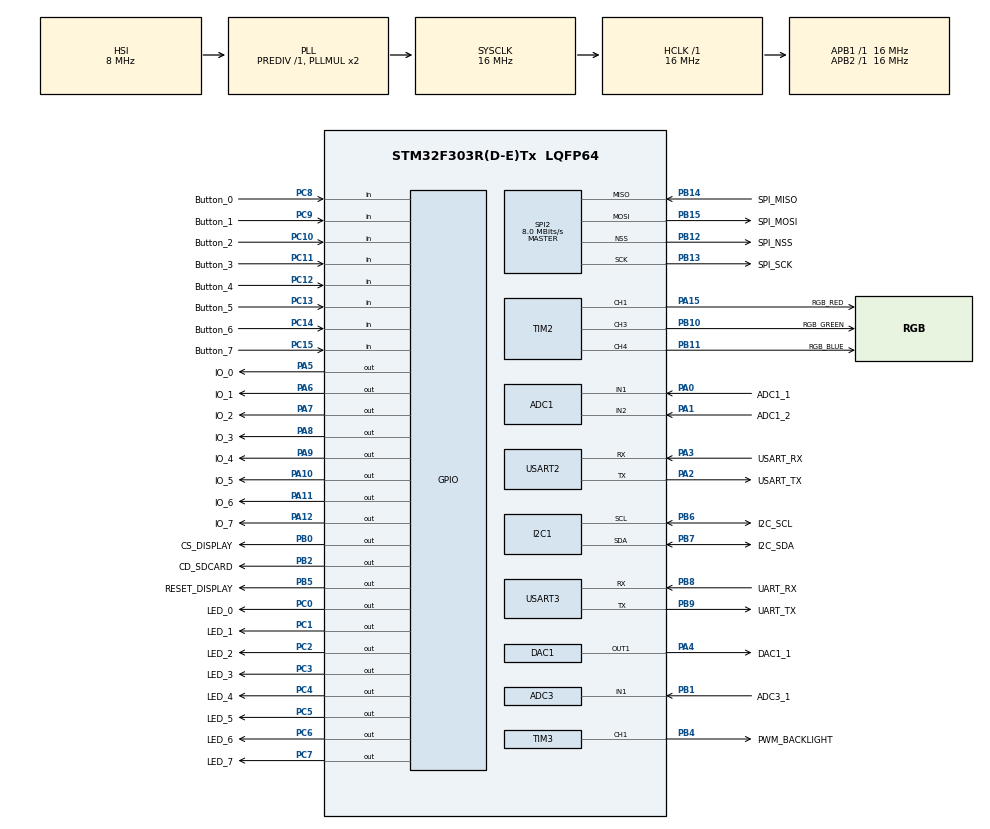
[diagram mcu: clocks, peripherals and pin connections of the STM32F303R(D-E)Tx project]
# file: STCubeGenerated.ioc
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ADC1.Channel-0\#ChannelRegularConversion=ADC_CHANNEL_1
ADC1.NbrOfConversionFlag=1
ADC1.Offset-0\#ChannelRegularConversion=0
ADC1.OffsetNumber-0\#ChannelRegularConversion=ADC_OFFSET_NONE
ADC1.Rank-0\#ChannelRegularConversion=1
ADC1.SamplingTime-0\#ChannelRegularConversion=ADC_SAMPLETIME_1CYCLE_5
ADC1.SingleDiff-0\#ChannelRegularConversion=ADC_DIFFERENTIAL_ENDED
ADC1.master=1
ADC3.Channel-0\#ChannelRegularConversion=ADC_CHANNEL_1
ADC3.NbrOfConversionFlag=1
ADC3.Offset-0\#ChannelRegularConversion=0
ADC3.OffsetNumber-0\#ChannelRegularConversion=ADC_OFFSET_NONE
ADC3.Rank-0\#ChannelRegularConversion=1
ADC3.SamplingTime-0\#ChannelRegularConversion=ADC_SAMPLETIME_1CYCLE_5
ADC3.master=1
Mcu.Family=STM32F3
Mcu.Name=STM32F303R(D-E)Tx
Mcu.Package=LQFP64
NVIC.PriorityGroup=NVIC_PRIORITYGROUP_0
PA0.GPIO_Label=ADC1_1
PA0.Mode=IN1-Differential
PA0.Signal=ADC1_IN1
PA1.GPIO_Label=ADC1_2
PA1.Mode=IN1-Differential
PA1.Signal=ADC1_IN2
PA10.GPIO_Label=IO_5
PA10.Signal=GPIO_Output
PA11.GPIO_Label=IO_6
PA11.Signal=GPIO_Output
PA12.GPIO_Label=IO_7
PA12.Signal=GPIO_Output
PA13.GPIO_Label=TMS
PA13.Mode=Serial_Wire
PA13.Signal=SYS_JTMS-SWDIO
PA14.GPIO_Label=TCK
PA14.Mode=Serial_Wire
PA14.Signal=SYS_JTCK-SWCLK
PA15.GPIO_Label=RGB_RED
PA15.Signal=S_TIM2_CH1_ETR
PA2.GPIO_Label=USART_TX
PA2.GPIO_Mode=GPIO_MODE_AF_PP
PA2.GPIO_PuPd=GPIO_NOPULL
PA2.GPIO_Speed=GPIO_SPEED_FREQ_LOW
PA2.Mode=Asynchronous
PA2.Signal=USART2_TX
PA3.GPIO_Label=USART_RX
PA3.GPIO_Mode=GPIO_MODE_AF_PP
PA3.GPIO_PuPd=GPIO_NOPULL
PA3.GPIO_Speed=GPIO_SPEED_FREQ_LOW
PA3.Mode=Asynchronous
PA3.Signal=USART2_RX
PA4.GPIO_Label=DAC1_1
PA4.Signal=COMP_DAC11_group
PA5.GPIO_Label=IO_0
PA5.Signal=GPIO_Output
PA6.GPIO_Label=IO_1
PA6.Signal=GPIO_Output
PA7.GPIO_Label=IO_2
PA7.Signal=GPIO_Output
PA8.GPIO_Label=IO_3
PA8.Signal=GPIO_Output
PA9.GPIO_Label=IO_4
PA9.Signal=GPIO_Output
PB0.GPIO_Label=CS_DISPLAY
PB0.Signal=GPIO_Output
PB1.GPIO_Label=ADC3_1
PB1.Mode=IN1-Single-Ended
PB1.Signal=ADC3_IN1
PB10.GPIO_Label=RGB_GREEN
PB10.Signal=S_TIM2_CH3
PB11.GPIO_Label=RGB_BLUE
PB11.Signal=S_TIM2_CH4
PB12.GPIO_Label=SPI_NSS
PB12.Mode=NSS_Signal_Hard_Output
PB12.Signal=SPI2_NSS
PB13.GPIO_Label=SPI_SCK
PB13.Mode=Full_Duplex_Master
PB13.Signal=SPI2_SCK
PB14.GPIO_Label=SPI_MISO
PB14.Mode=Full_Duplex_Master
PB14.Signal=SPI2_MISO
PB15.GPIO_Label=SPI_MOSI
PB15.Mode=Full_Duplex_Master
PB15.Signal=SPI2_MOSI
PB2.GPIO_Label=CD_SDCARD
PB2.Signal=GPIO_Output
PB3.GPIO_Label=SWO
PB3.Signal=SYS_JTDO-TRACESWO
PB4.GPIO_Label=PWM_BACKLIGHT
PB4.Signal=S_TIM3_CH1
PB5.GPIO_Label=RESET_DISPLAY
PB5.Signal=GPIO_Output
PB6.GPIO_Label=I2C_SCL
PB6.GPIO_Pu=GPIO_PULLUP
PB6.Mode=I2C
PB6.Signal=I2C1_SCL
PB7.GPIO_Label=I2C_SDA
PB7.GPIO_Pu=GPIO_PULLUP
PB7.Mode=I2C
PB7.Signal=I2C1_SDA
PB8.GPIO_Label=UART_RX
PB8.Mode=Asynchronous
PB8.Signal=USART3_RX
PB9.GPIO_Label=UART_TX
PB9.Mode=Asynchronous
PB9.Signal=USART3_TX
PC0.GPIO_Label=LED_0
PC0.Signal=GPIO_Output
PC1.GPIO_Label=LED_1
PC1.Signal=GPIO_Output
PC10.GPIO_Label=Button_2
PC10.Signal=GPIO_Input
PC11.GPIO_Label=Button_3
PC11.Signal=GPIO_Input
PC12.GPIO_Label=Button_4
PC12.Signal=GPIO_Input
PC13.GPIO_Label=Button_5
PC13.Signal=GPIO_Input
PC14-OSC32_IN.GPIO_Label=Button_6
PC14-OSC32_IN.GPIO_PuPd=GPIO_NOPULL
PC14-OSC32_IN.Signal=GPIO_Input
PC15-OSC32_OUT.GPIO_Label=Button_7
PC15-OSC32_OUT.GPIO_PuPd=GPIO_NOPULL
PC15-OSC32_OUT.Signal=GPIO_Input
PC2.GPIO_Label=LED_2
PC2.Signal=GPIO_Output
PC3.GPIO_Label=LED_3
PC3.Signal=GPIO_Output
PC4.GPIO_Label=LED_4
PC4.Signal=GPIO_Output
PC5.GPIO_Label=LED_5
PC5.Signal=GPIO_Output
PC6.GPIO_Label=LED_6
PC6.Signal=GPIO_Output
PC7.GPIO_Label=LED_7
PC7.Signal=GPIO_Output
PC8.GPIO_Label=Button_0
PC8.Signal=GPIO_Input
PC9.GPIO_Label=Button_1
PC9.Signal=GPIO_Input
PF0-OSC_IN.Signal=RCC_OSC_IN
PF1-OSC_OUT.Signal=RCC_OSC_OUT
ProjectManager.HeapSize=0x200
ProjectManager.StackSize=0x400
ProjectManager.TargetToolchain=MDK-ARM V5.32
RCC.AHBFreq_Value=16000000
RCC.APB1Freq_Value=16000000
RCC.APB1TimFreq_Value=16000000
RCC.APB2Freq_Value=16000000
RCC.APB2TimFreq_Value=16000000
RCC.CortexFreq_Value=16000000
RCC.HCLKFreq_Value=16000000
RCC.HSE_VALUE=8000000
RCC.HSI_VALUE=8000000
RCC.LSE_VALUE=32768
RCC.SYSCLKFreq_VALUE=16000000
RCC.SYSCLKSourceVirtual=RCC_SYSCLKSOURCE_PLLCLK
RCC.USBFreq_Value=16000000
SH.COMP_DAC11_group.0=DAC1_OUT1,DAC_OUT1
SH.S_TIM2_CH1_ETR.0=TIM2_CH1,PWM Generation1 CH1
SH.S_TIM2_CH3.0=TIM2_CH3,PWM Generation3 CH3
SH.S_TIM2_CH4.0=TIM2_CH4,PWM Generation4 CH4
SH.S_TIM3_CH1.0=TIM3_CH1,PWM Generation1 CH1
SPI2.CalculateBaudRate=8.0 MBits/s
SPI2.Direction=SPI_DIRECTION_2LINES
SPI2.Mode=SPI_MODE_MASTER
SPI2.VirtualNSS=VM_NSSHARD
SPI2.VirtualType=VM_MASTER
TIM2.Channel-PWM\ Generation1\ CH1=TIM_CHANNEL_1
TIM2.Channel-PWM\ Generation3\ CH3=TIM_CHANNEL_3
TIM2.Channel-PWM\ Generation4\ CH4=TIM_CHANNEL_4
TIM3.Channel-PWM\ Generation1\ CH1=TIM_CHANNEL_1
USART2.VirtualMode-Asynchronous=VM_ASYNC
USART3.VirtualMode-Asynchronous=VM_ASYNC
board=NUCLEO-F303RE

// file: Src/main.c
/* USER CODE BEGIN Header */
/**
  ******************************************************************************
  * @file           : main.c
  * @brief          : Main program body
  ******************************************************************************
  * @attention
  *
  * Copyright (c) 2022 STMicroelectronics.
  * All rights reserved.
  *
  * This software is licensed under terms that can be found in the LICENSE file
  * in the root directory of this software component.
  * If no LICENSE file comes with this software, it is provided AS-IS.
  *
  ******************************************************************************
  */
/* USER CODE END Header */
#include "main.h"

/* USER CODE BEGIN PD */
#define BUTTONS	(*((volatile uint32_t *) (0x48000800 + 0x10 + 1)))		// BASE Address PORT C + Offset for Input Register + Byte Shift (>> 8, to skip LEDs)
#define LEDS		(*((volatile uint32_t *) (0x48000800 + 0x14)))				// BASE Address PORT C + Offset for Output Register

/* USER CODE END PD */

ADC_HandleTypeDef hadc1;
ADC_HandleTypeDef hadc3;

DAC_HandleTypeDef hdac1;

I2C_HandleTypeDef hi2c1;

SPI_HandleTypeDef hspi2;

TIM_HandleTypeDef htim2;
TIM_HandleTypeDef htim3;

UART_HandleTypeDef huart2;
UART_HandleTypeDef huart3;

void SystemClock_Config(void);
static void MX_GPIO_Init(void);
static void MX_ADC1_Init(void);
static void MX_ADC3_Init(void);
static void MX_DAC1_Init(void);
static void MX_I2C1_Init(void);
static void MX_SPI2_Init(void);
static void MX_TIM2_Init(void);
static void MX_TIM3_Init(void);
static void MX_USART2_UART_Init(void);
static void MX_USART3_UART_Init(void);

int main(void)
{

  /* MCU Configuration--------------------------------------------------------*/

  /* Reset of all peripherals, Initializes the Flash interface and the Systick. */
  HAL_Init();

  /* Configure the system clock */
  SystemClock_Config();

  /* Initialize all configured peripherals */
  MX_GPIO_Init();
  MX_ADC1_Init();
  MX_ADC3_Init();
  MX_DAC1_Init();
  MX_I2C1_Init();
  MX_SPI2_Init();
  MX_TIM2_Init();
  MX_TIM3_Init();
  MX_USART2_UART_Init();
  MX_USART3_UART_Init();

  /* Infinite loop */
  while (1)
  {

    /* USER CODE BEGIN 3 */
		unsigned char buttons = BUTTONS;
		LEDS = buttons;
  }
  /* USER CODE END 3 */
}

void SystemClock_Config(void)
{
  RCC_OscInitTypeDef RCC_OscInitStruct = {0};
  RCC_ClkInitTypeDef RCC_ClkInitStruct = {0};
  RCC_PeriphCLKInitTypeDef PeriphClkInit = {0};

  /** Initializes the RCC Oscillators according to the specified parameters
  * in the RCC_OscInitTypeDef structure.
  */
  RCC_OscInitStruct.OscillatorType = RCC_OSCILLATORTYPE_HSI;
  RCC_OscInitStruct.HSIState = RCC_HSI_ON;
  RCC_OscInitStruct.HSICalibrationValue = RCC_HSICALIBRATION_DEFAULT;
  RCC_OscInitStruct.PLL.PLLState = RCC_PLL_ON;
  RCC_OscInitStruct.PLL.PLLSource = RCC_PLLSOURCE_HSI;
  RCC_OscInitStruct.PLL.PLLMUL = RCC_PLL_MUL2;
  RCC_OscInitStruct.PLL.PREDIV = RCC_PREDIV_DIV1;
  if (HAL_RCC_OscConfig(&RCC_OscInitStruct) != HAL_OK)
  {
    Error_Handler();
  }

  /** Initializes the CPU, AHB and APB buses clocks
  */
  RCC_ClkInitStruct.ClockType = RCC_CLOCKTYPE_HCLK|RCC_CLOCKTYPE_SYSCLK
                              |RCC_CLOCKTYPE_PCLK1|RCC_CLOCKTYPE_PCLK2;
  RCC_ClkInitStruct.SYSCLKSource = RCC_SYSCLKSOURCE_PLLCLK;
  RCC_ClkInitStruct.AHBCLKDivider = RCC_SYSCLK_DIV1;
  RCC_ClkInitStruct.APB1CLKDivider = RCC_HCLK_DIV1;
  RCC_ClkInitStruct.APB2CLKDivider = RCC_HCLK_DIV1;

  if (HAL_RCC_ClockConfig(&RCC_ClkInitStruct, FLASH_LATENCY_0) != HAL_OK)
  {
    Error_Handler();
  }
  PeriphClkInit.PeriphClockSelection = RCC_PERIPHCLK_USART2|RCC_PERIPHCLK_USART3
                              |RCC_PERIPHCLK_I2C1|RCC_PERIPHCLK_ADC12
                              |RCC_PERIPHCLK_ADC34|RCC_PERIPHCLK_TIM2
                              |RCC_PERIPHCLK_TIM34;
  PeriphClkInit.Usart2ClockSelection = RCC_USART2CLKSOURCE_PCLK1;
  PeriphClkInit.Usart3ClockSelection = RCC_USART3CLKSOURCE_PCLK1;
  PeriphClkInit.Adc12ClockSelection = RCC_ADC12PLLCLK_DIV1;
  PeriphClkInit.Adc34ClockSelection = RCC_ADC34PLLCLK_DIV1;
  PeriphClkInit.I2c1ClockSelection = RCC_I2C1CLKSOURCE_HSI;
  PeriphClkInit.Tim2ClockSelection = RCC_TIM2CLK_HCLK;
  PeriphClkInit.Tim34ClockSelection = RCC_TIM34CLK_HCLK;
  if (HAL_RCCEx_PeriphCLKConfig(&PeriphClkInit) != HAL_OK)
  {
    Error_Handler();
  }
}

static void MX_ADC1_Init(void)
{

  ADC_MultiModeTypeDef multimode = {0};
  ADC_ChannelConfTypeDef sConfig = {0};

  /** Common config
  */
  hadc1.Instance = ADC1;
  hadc1.Init.ClockPrescaler = ADC_CLOCK_ASYNC_DIV1;
  hadc1.Init.Resolution = ADC_RESOLUTION_12B;
  hadc1.Init.ScanConvMode = ADC_SCAN_DISABLE;
  hadc1.Init.ContinuousConvMode = DISABLE;
  hadc1.Init.DiscontinuousConvMode = DISABLE;
  hadc1.Init.ExternalTrigConvEdge = ADC_EXTERNALTRIGCONVEDGE_NONE;
  hadc1.Init.ExternalTrigConv = ADC_SOFTWARE_START;
  hadc1.Init.DataAlign = ADC_DATAALIGN_RIGHT;
  hadc1.Init.NbrOfConversion = 1;
  hadc1.Init.DMAContinuousRequests = DISABLE;
  hadc1.Init.EOCSelection = ADC_EOC_SINGLE_CONV;
  hadc1.Init.LowPowerAutoWait = DISABLE;
  hadc1.Init.Overrun = ADC_OVR_DATA_OVERWRITTEN;
  if (HAL_ADC_Init(&hadc1) != HAL_OK)
  {
    Error_Handler();
  }

  /** Configure the ADC multi-mode
  */
  multimode.Mode = ADC_MODE_INDEPENDENT;
  if (HAL_ADCEx_MultiModeConfigChannel(&hadc1, &multimode) != HAL_OK)
  {
    Error_Handler();
  }

  /** Configure Regular Channel
  */
  sConfig.Channel = ADC_CHANNEL_1;
  sConfig.Rank = ADC_REGULAR_RANK_1;
  sConfig.SingleDiff = ADC_DIFFERENTIAL_ENDED;
  sConfig.SamplingTime = ADC_SAMPLETIME_1CYCLE_5;
  sConfig.OffsetNumber = ADC_OFFSET_NONE;
  sConfig.Offset = 0;
  if (HAL_ADC_ConfigChannel(&hadc1, &sConfig) != HAL_OK)
  {
    Error_Handler();
  }

}

static void MX_ADC3_Init(void)
{

  ADC_MultiModeTypeDef multimode = {0};
  ADC_ChannelConfTypeDef sConfig = {0};

  /** Common config
  */
  hadc3.Instance = ADC3;
  hadc3.Init.ClockPrescaler = ADC_CLOCK_ASYNC_DIV1;
  hadc3.Init.Resolution = ADC_RESOLUTION_12B;
  hadc3.Init.ScanConvMode = ADC_SCAN_DISABLE;
  hadc3.Init.ContinuousConvMode = DISABLE;
  hadc3.Init.DiscontinuousConvMode = DISABLE;
  hadc3.Init.ExternalTrigConvEdge = ADC_EXTERNALTRIGCONVEDGE_NONE;
  hadc3.Init.ExternalTrigConv = ADC_SOFTWARE_START;
  hadc3.Init.DataAlign = ADC_DATAALIGN_RIGHT;
  hadc3.Init.NbrOfConversion = 1;
  hadc3.Init.DMAContinuousRequests = DISABLE;
  hadc3.Init.EOCSelection = ADC_EOC_SINGLE_CONV;
  hadc3.Init.LowPowerAutoWait = DISABLE;
  hadc3.Init.Overrun = ADC_OVR_DATA_OVERWRITTEN;
  if (HAL_ADC_Init(&hadc3) != HAL_OK)
  {
    Error_Handler();
  }

  /** Configure the ADC multi-mode
  */
  multimode.Mode = ADC_MODE_INDEPENDENT;
  if (HAL_ADCEx_MultiModeConfigChannel(&hadc3, &multimode) != HAL_OK)
  {
    Error_Handler();
  }

  /** Configure Regular Channel
  */
  sConfig.Channel = ADC_CHANNEL_1;
  sConfig.Rank = ADC_REGULAR_RANK_1;
  sConfig.SingleDiff = ADC_SINGLE_ENDED;
  sConfig.SamplingTime = ADC_SAMPLETIME_1CYCLE_5;
  sConfig.OffsetNumber = ADC_OFFSET_NONE;
  sConfig.Offset = 0;
  if (HAL_ADC_ConfigChannel(&hadc3, &sConfig) != HAL_OK)
  {
    Error_Handler();
  }

}

static void MX_DAC1_Init(void)
{

  DAC_ChannelConfTypeDef sConfig = {0};

  /** DAC Initialization
  */
  hdac1.Instance = DAC1;
  if (HAL_DAC_Init(&hdac1) != HAL_OK)
  {
    Error_Handler();
  }

  /** DAC channel OUT1 config
  */
  sConfig.DAC_Trigger = DAC_TRIGGER_NONE;
  sConfig.DAC_OutputBuffer = DAC_OUTPUTBUFFER_ENABLE;
  if (HAL_DAC_ConfigChannel(&hdac1, &sConfig, DAC_CHANNEL_1) != HAL_OK)
  {
    Error_Handler();
  }

}

static void MX_I2C1_Init(void)
{

  hi2c1.Instance = I2C1;
  hi2c1.Init.Timing = 0x2000090E;
  hi2c1.Init.OwnAddress1 = 0;
  hi2c1.Init.AddressingMode = I2C_ADDRESSINGMODE_7BIT;
  hi2c1.Init.DualAddressMode = I2C_DUALADDRESS_DISABLE;
  hi2c1.Init.OwnAddress2 = 0;
  hi2c1.Init.OwnAddress2Masks = I2C_OA2_NOMASK;
  hi2c1.Init.GeneralCallMode = I2C_GENERALCALL_DISABLE;
  hi2c1.Init.NoStretchMode = I2C_NOSTRETCH_DISABLE;
  if (HAL_I2C_Init(&hi2c1) != HAL_OK)
  {
    Error_Handler();
  }

  /** Configure Analogue filter
  */
  if (HAL_I2CEx_ConfigAnalogFilter(&hi2c1, I2C_ANALOGFILTER_ENABLE) != HAL_OK)
  {
    Error_Handler();
  }

  /** Configure Digital filter
  */
  if (HAL_I2CEx_ConfigDigitalFilter(&hi2c1, 0) != HAL_OK)
  {
    Error_Handler();
  }

}

static void MX_SPI2_Init(void)
{

  /* SPI2 parameter configuration*/
  hspi2.Instance = SPI2;
  hspi2.Init.Mode = SPI_MODE_MASTER;
  hspi2.Init.Direction = SPI_DIRECTION_2LINES;
  hspi2.Init.DataSize = SPI_DATASIZE_4BIT;
  hspi2.Init.CLKPolarity = SPI_POLARITY_LOW;
  hspi2.Init.CLKPhase = SPI_PHASE_1EDGE;
  hspi2.Init.NSS = SPI_NSS_HARD_OUTPUT;
  hspi2.Init.BaudRatePrescaler = SPI_BAUDRATEPRESCALER_2;
  hspi2.Init.FirstBit = SPI_FIRSTBIT_MSB;
  hspi2.Init.TIMode = SPI_TIMODE_DISABLE;
  hspi2.Init.CRCCalculation = SPI_CRCCALCULATION_DISABLE;
  hspi2.Init.CRCPolynomial = 7;
  hspi2.Init.CRCLength = SPI_CRC_LENGTH_DATASIZE;
  hspi2.Init.NSSPMode = SPI_NSS_PULSE_ENABLE;
  if (HAL_SPI_Init(&hspi2) != HAL_OK)
  {
    Error_Handler();
  }

}

static void MX_TIM2_Init(void)
{

  TIM_MasterConfigTypeDef sMasterConfig = {0};
  TIM_OC_InitTypeDef sConfigOC = {0};

  htim2.Instance = TIM2;
  htim2.Init.Prescaler = 0;
  htim2.Init.CounterMode = TIM_COUNTERMODE_UP;
  htim2.Init.Period = 4294967295;
  htim2.Init.ClockDivision = TIM_CLOCKDIVISION_DIV1;
  htim2.Init.AutoReloadPreload = TIM_AUTORELOAD_PRELOAD_DISABLE;
  if (HAL_TIM_PWM_Init(&htim2) != HAL_OK)
  {
    Error_Handler();
  }
  sMasterConfig.MasterOutputTrigger = TIM_TRGO_RESET;
  sMasterConfig.MasterSlaveMode = TIM_MASTERSLAVEMODE_DISABLE;
  if (HAL_TIMEx_MasterConfigSynchronization(&htim2, &sMasterConfig) != HAL_OK)
  {
    Error_Handler();
  }
  sConfigOC.OCMode = TIM_OCMODE_PWM1;
  sConfigOC.Pulse = 0;
  sConfigOC.OCPolarity = TIM_OCPOLARITY_HIGH;
  sConfigOC.OCFastMode = TIM_OCFAST_DISABLE;
  if (HAL_TIM_PWM_ConfigChannel(&htim2, &sConfigOC, TIM_CHANNEL_1) != HAL_OK)
  {
    Error_Handler();
  }
  if (HAL_TIM_PWM_ConfigChannel(&htim2, &sConfigOC, TIM_CHANNEL_3) != HAL_OK)
  {
    Error_Handler();
  }
  if (HAL_TIM_PWM_ConfigChannel(&htim2, &sConfigOC, TIM_CHANNEL_4) != HAL_OK)
  {
    Error_Handler();
  }
  HAL_TIM_MspPostInit(&htim2);

}

static void MX_TIM3_Init(void)
{

  TIM_MasterConfigTypeDef sMasterConfig = {0};
  TIM_OC_InitTypeDef sConfigOC = {0};

  htim3.Instance = TIM3;
  htim3.Init.Prescaler = 0;
  htim3.Init.CounterMode = TIM_COUNTERMODE_UP;
  htim3.Init.Period = 65535;
  htim3.Init.ClockDivision = TIM_CLOCKDIVISION_DIV1;
  htim3.Init.AutoReloadPreload = TIM_AUTORELOAD_PRELOAD_DISABLE;
  if (HAL_TIM_PWM_Init(&htim3) != HAL_OK)
  {
    Error_Handler();
  }
  sMasterConfig.MasterOutputTrigger = TIM_TRGO_RESET;
  sMasterConfig.MasterSlaveMode = TIM_MASTERSLAVEMODE_DISABLE;
  if (HAL_TIMEx_MasterConfigSynchronization(&htim3, &sMasterConfig) != HAL_OK)
  {
    Error_Handler();
  }
  sConfigOC.OCMode = TIM_OCMODE_PWM1;
  sConfigOC.Pulse = 0;
  sConfigOC.OCPolarity = TIM_OCPOLARITY_HIGH;
  sConfigOC.OCFastMode = TIM_OCFAST_DISABLE;
  if (HAL_TIM_PWM_ConfigChannel(&htim3, &sConfigOC, TIM_CHANNEL_1) != HAL_OK)
  {
    Error_Handler();
  }
  HAL_TIM_MspPostInit(&htim3);

}

static void MX_USART2_UART_Init(void)
{

  huart2.Instance = USART2;
  huart2.Init.BaudRate = 38400;
  huart2.Init.WordLength = UART_WORDLENGTH_8B;
  huart2.Init.StopBits = UART_STOPBITS_1;
  huart2.Init.Parity = UART_PARITY_NONE;
  huart2.Init.Mode = UART_MODE_TX_RX;
  huart2.Init.HwFlowCtl = UART_HWCONTROL_NONE;
  huart2.Init.OverSampling = UART_OVERSAMPLING_16;
  huart2.Init.OneBitSampling = UART_ONE_BIT_SAMPLE_DISABLE;
  huart2.AdvancedInit.AdvFeatureInit = UART_ADVFEATURE_NO_INIT;
  if (HAL_UART_Init(&huart2) != HAL_OK)
  {
    Error_Handler();
  }

}

static void MX_USART3_UART_Init(void)
{

  huart3.Instance = USART3;
  huart3.Init.BaudRate = 38400;
  huart3.Init.WordLength = UART_WORDLENGTH_8B;
  huart3.Init.StopBits = UART_STOPBITS_1;
  huart3.Init.Parity = UART_PARITY_NONE;
  huart3.Init.Mode = UART_MODE_TX_RX;
  huart3.Init.HwFlowCtl = UART_HWCONTROL_NONE;
  huart3.Init.OverSampling = UART_OVERSAMPLING_16;
  huart3.Init.OneBitSampling = UART_ONE_BIT_SAMPLE_DISABLE;
  huart3.AdvancedInit.AdvFeatureInit = UART_ADVFEATURE_NO_INIT;
  if (HAL_UART_Init(&huart3) != HAL_OK)
  {
    Error_Handler();
  }

}

static void MX_GPIO_Init(void)
{
  GPIO_InitTypeDef GPIO_InitStruct = {0};

  /* GPIO Ports Clock Enable */
  __HAL_RCC_GPIOC_CLK_ENABLE();
  __HAL_RCC_GPIOF_CLK_ENABLE();
  __HAL_RCC_GPIOA_CLK_ENABLE();
  __HAL_RCC_GPIOB_CLK_ENABLE();

  /*Configure GPIO pin Output Level */
  HAL_GPIO_WritePin(GPIOC, LED_0_Pin|LED_1_Pin|LED_2_Pin|LED_3_Pin
                          |LED_4_Pin|LED_5_Pin|LED_6_Pin|LED_7_Pin, GPIO_PIN_RESET);

  /*Configure GPIO pin Output Level */
  HAL_GPIO_WritePin(GPIOA, IO_0_Pin|IO_1_Pin|IO_2_Pin|IO_3_Pin
                          |IO_4_Pin|IO_5_Pin|IO_6_Pin|IO_7_Pin, GPIO_PIN_RESET);

  /*Configure GPIO pin Output Level */
  HAL_GPIO_WritePin(GPIOB, CS_DISPLAY_Pin|CD_SDCARD_Pin|RESET_DISPLAY_Pin, GPIO_PIN_RESET);

  /*Configure GPIO pins : Button_5_Pin Button_6_Pin Button_7_Pin Button_0_Pin
                           Button_1_Pin Button_2_Pin Button_3_Pin Button_4_Pin */
  GPIO_InitStruct.Pin = Button_5_Pin|Button_6_Pin|Button_7_Pin|Button_0_Pin
                          |Button_1_Pin|Button_2_Pin|Button_3_Pin|Button_4_Pin;
  GPIO_InitStruct.Mode = GPIO_MODE_INPUT;
  GPIO_InitStruct.Pull = GPIO_NOPULL;
  HAL_GPIO_Init(GPIOC, &GPIO_InitStruct);

  /*Configure GPIO pins : LED_0_Pin LED_1_Pin LED_2_Pin LED_3_Pin
                           LED_4_Pin LED_5_Pin LED_6_Pin LED_7_Pin */
  GPIO_InitStruct.Pin = LED_0_Pin|LED_1_Pin|LED_2_Pin|LED_3_Pin
                          |LED_4_Pin|LED_5_Pin|LED_6_Pin|LED_7_Pin;
  GPIO_InitStruct.Mode = GPIO_MODE_OUTPUT_PP;
  GPIO_InitStruct.Pull = GPIO_NOPULL;
  GPIO_InitStruct.Speed = GPIO_SPEED_FREQ_LOW;
  HAL_GPIO_Init(GPIOC, &GPIO_InitStruct);

  /*Configure GPIO pins : IO_0_Pin IO_1_Pin IO_2_Pin IO_3_Pin
                           IO_4_Pin IO_5_Pin IO_6_Pin IO_7_Pin */
  GPIO_InitStruct.Pin = IO_0_Pin|IO_1_Pin|IO_2_Pin|IO_3_Pin
                          |IO_4_Pin|IO_5_Pin|IO_6_Pin|IO_7_Pin;
  GPIO_InitStruct.Mode = GPIO_MODE_OUTPUT_PP;
  GPIO_InitStruct.Pull = GPIO_NOPULL;
  GPIO_InitStruct.Speed = GPIO_SPEED_FREQ_LOW;
  HAL_GPIO_Init(GPIOA, &GPIO_InitStruct);

  /*Configure GPIO pins : CS_DISPLAY_Pin CD_SDCARD_Pin RESET_DISPLAY_Pin */
  GPIO_InitStruct.Pin = CS_DISPLAY_Pin|CD_SDCARD_Pin|RESET_DISPLAY_Pin;
  GPIO_InitStruct.Mode = GPIO_MODE_OUTPUT_PP;
  GPIO_InitStruct.Pull = GPIO_NOPULL;
  GPIO_InitStruct.Speed = GPIO_SPEED_FREQ_LOW;
  HAL_GPIO_Init(GPIOB, &GPIO_InitStruct);

}

void Error_Handler(void)
{
  __disable_irq();
  while (1)
  {
  }
}
